# STM32G030 register map
File version: 1.6
CPU: CM0 r0p1, little endian, MPU, no FPU, 2 interrupt priority bits
Registers are 32-bit, read-write, reset 0x0 unless marked. A register's access mark holds for its fields unless they carry their own. Offsets are from the block's base; [hi:lo] are bit positions; {n}, {i} and the like mark numbered series; 'fields as' and 'values as' point back to an identical list.

## CRC — Cyclic redundancy check calculation unit
Base 0x40023000
0x00 DR reset 0xFFFFFFFF — Data register
  [31:0] DR — Data register bits
0x00 DR8 8-bit reset 0xFF (alternate view of DR) — Data register - byte sized
  [7:0] DR8 — Data register bits
0x00 DR16 16-bit reset 0xFFFF (alternate view of DR) — Data register - half-word sized
  [15:0] DR16 — Data register bits
0x04 IDR — Independent data register
  [31:0] IDR — General-purpose 32-bit data register bits
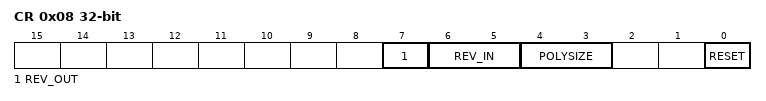
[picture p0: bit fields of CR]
0x08 CR access per field — Control register
  [7] REV_OUT rw — Reverse output data
    0=Normal (Bit order not affected); 1=Reversed (Bit reversed output)
  [6:5] REV_IN rw — Reverse input data
    0=Normal (Bit order not affected); 1=Byte (Bit reversal done by byte); 2=HalfWord (Bit reversal done by half-word); 3=Word (Bit reversal done by word)
  [4:3] POLYSIZE rw — Polynomial size
    0=32-bit polynomial; 1=16-bit polynomial; 2=8-bit polynomial; 3=7-bit polynomial
  [0] RESET wo — RESET bit
    1=Resets the CRC calculation unit and sets the data register to 0xFFFF FFFF
0x10 INIT reset 0xFFFFFFFF — Initial CRC value
  [31:0] INIT — Programmable initial CRC value
0x14 POL reset 0x4C11DB7 — polynomial
  [31:0] POL — Programmable polynomial

## EXTI — External interrupt/event controller
Base 0x40021800
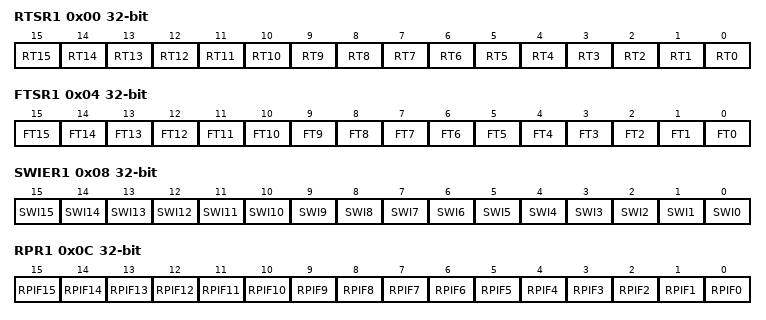
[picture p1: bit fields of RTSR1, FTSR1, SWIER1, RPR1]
0x00 RTSR1 — EXTI rising trigger selection register
  [all] fields
    0=Disabled (Rising edge trigger is disabled); 1=Enabled (Rising edge trigger is enabled)
  [n] RT{n} (n=0..15) — Rising trigger event configuration bit of Configurable Event line
0x04 FTSR1 — EXTI falling trigger selection register
  [all] fields
    0=Disabled (Falling edge trigger is disabled); 1=Enabled (Falling edge trigger is enabled)
  [n] FT{n} (n=0..15) — Falling trigger event configuration bit of configurable line
0x08 SWIER1 — EXTI software interrupt event register
  [all] fields
    on write: 1=Pend (Generates an interrupt request)
  [n] SWI{n} (n=0..15) — Software rising edge event trigger on line
0x0C RPR1 — EXTI rising edge pending register
  [all] fields
    on read: 0=NotPending (No trigger request occurred); 1=Pending (Selected trigger request occurred) | on write: 1=Clears pending bit
  [n] RPIF{n} write-1-clears (n=6..15) — Rising edge event pending for configurable line
  [5] RPIF5 write-1-clears — configurable event inputs x rising edge Pending bit
  [n] RPIF{n} write-1-clears (n=0..4) — Rising edge event pending for configurable line
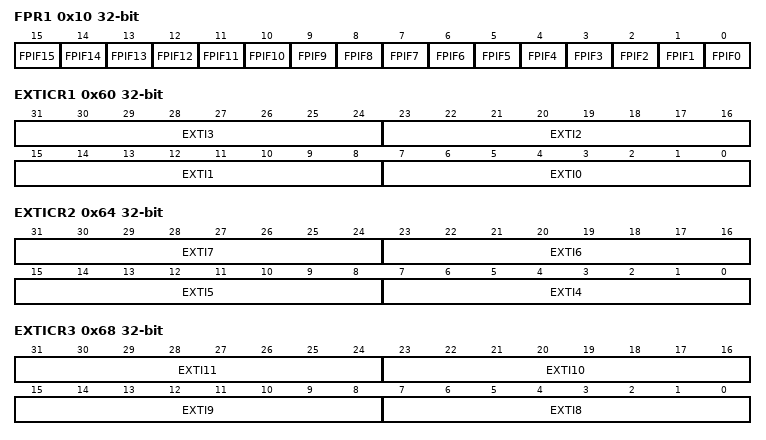
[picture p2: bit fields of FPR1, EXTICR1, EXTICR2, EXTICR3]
0x10 FPR1 — EXTI falling edge pending register
  [all] fields
    values as the fields of RPR1
  [n] FPIF{n} write-1-clears (n=0..15) — Falling edge event pending for configurable line
0x60 EXTICR1 — EXTI external interrupt selection register
  [all] fields
    0=PA (Select PAx as the source input for the EXTIx external interrupt); 1=PB (Select PBx as the source input for the EXTIx external interrupt); 2=PC (Select PCx as the source input for the EXTIx external interrupt); 3=PD (Select PDx as the source input for the EXTIx external interrupt); 5=PF (Select PFx as the source input for the EXTIx external interrupt)
  [8n+7:8n] EXTI{n} (n=0..3) — GPIO port selection
0x64 EXTICR2 — EXTI external interrupt selection register
  [all] fields
    values as the fields of EXTICR1
  [8n-25:8n-32] EXTI{n} (n=4..7) — GPIO port selection
0x68 EXTICR3 — EXTI external interrupt selection register
  [all] fields
    values as the fields of EXTICR1
  [8n-57:8n-64] EXTI{n} (n=8..11) — GPIO port selection
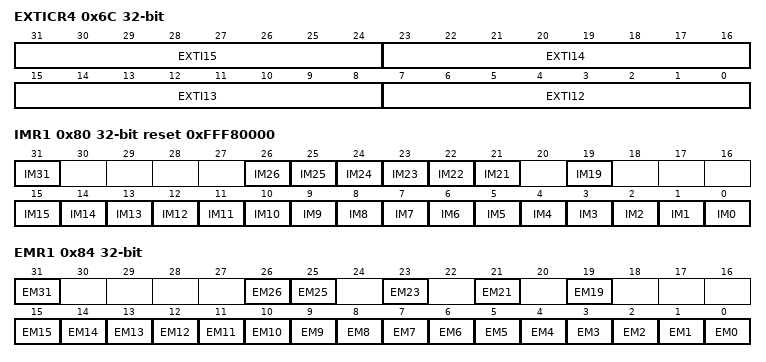
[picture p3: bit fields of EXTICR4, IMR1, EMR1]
0x6C EXTICR4 — EXTI external interrupt selection register
  [all] fields
    values as the fields of EXTICR1
  [8n-89:8n-96] EXTI{n} (n=12..15) — GPIO port selection
0x80 IMR1 reset 0xFFF80000 — EXTI CPU wakeup with interrupt mask register
  [all] fields
    0=Masked (Interrupt request line is masked); 1=Unmasked (Interrupt request line is unmasked)
  [31] IM31 — CPU wakeup with interrupt mask on event input
  [n] IM{n} (n=21..26) — CPU wakeup with interrupt mask on event input
  [19] IM19 — CPU wakeup with interrupt mask on event input
  [n] IM{n} (n=0..15) — CPU wakeup with interrupt mask on event input
0x84 EMR1 (alternate view of IMR1) — EXTI CPU wakeup with event mask register
  [all] fields
    0=Masked (Event request line is masked); 1=Unmasked (Event request line is unmasked)
  [31] EM31 — CPU wakeup with event mask on event input
  [26] EM26 — CPU wakeup with event mask on event input
  [25] EM25 — CPU wakeup with event mask on event input
  [23] EM23 — CPU wakeup with event mask on event input
  [21] EM21 — CPU wakeup with event mask on event input
  [19] EM19 — CPU wakeup with event mask on event input
  [n] EM{n} (n=0..15) — CPU wakeup with event mask on event input

## VREFBUF — System configuration controller
Base 0x40010030
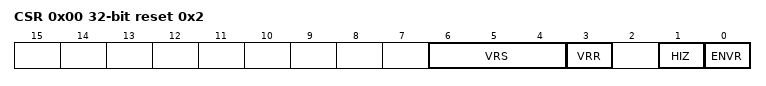
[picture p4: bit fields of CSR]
0x00 CSR access per field reset 0x2 — VREFBUF control and status register
  [6:4] VRS rw — Voltage reference scale These bits select the value generated by the voltage reference buffer. Other: Reserved
  [3] VRR ro — Voltage reference buffer ready
  [1] HIZ rw — High impedance mode This bit controls the analog switch to connect or not the VREF+ pin. Refer to Table196: VREF buffer modes for the mode descriptions depending on ENVR bit configuration.
  [0] ENVR rw — Voltage reference buffer mode enable This bit is used to enable the voltage reference buffer mode.
0x04 CCR — VREFBUF calibration control register
  [5:0] TRIM — Trimming code These bits are automatically initialized after reset with the trimming value stored in the Flash memory during the production test. Writing into these bits allows to tune the internal reference buffer voltage.

## DBG — MCU debug component
Base 0x40015800
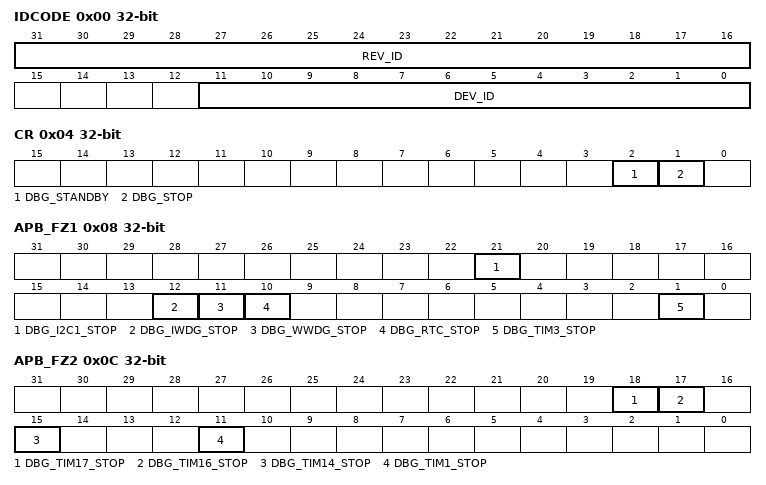
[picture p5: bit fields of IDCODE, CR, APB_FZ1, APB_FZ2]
0x00 IDCODE ro — DBGMCU_IDCODE
  [31:16] REV_ID — Revision identifie
  [11:0] DEV_ID — Device identifier
0x04 CR — Debug MCU configuration register
  [2] DBG_STANDBY — Debug Standby mode
  [1] DBG_STOP — Debug Stop mode
0x08 APB_FZ1 — Debug MCU APB1 freeze register1
  [21] DBG_I2C1_STOP — I2C1 SMBUS timeout counter stopped when core is halted
  [12] DBG_IWDG_STOP — Independent watchdog counter stopped when core is halted
  [11] DBG_WWDG_STOP — Window watchdog counter stopped when core is halted
  [10] DBG_RTC_STOP — RTC counter stopped when core is halted
  [1] DBG_TIM3_STOP — TIM3 counter stopped when core is halted
0x0C APB_FZ2 — Debug MCU APB1 freeze register 2
  [18] DBG_TIM17_STOP
  [17] DBG_TIM16_STOP
  [15] DBG_TIM14_STOP
  [11] DBG_TIM1_STOP — TIM1 counter stopped when core is halted
